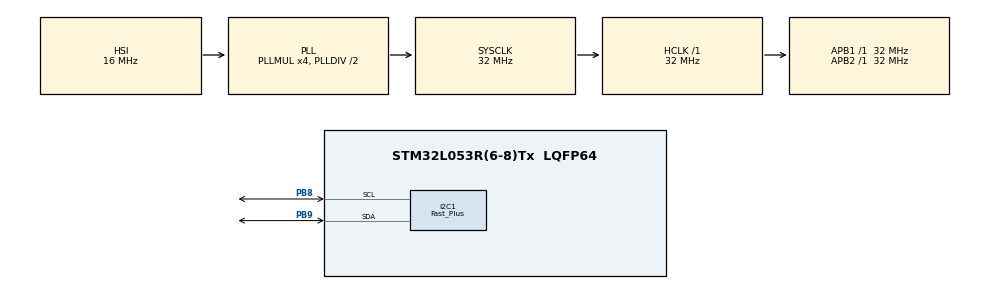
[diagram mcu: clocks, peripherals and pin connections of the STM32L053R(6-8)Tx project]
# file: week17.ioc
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I2C1.I2C_Speed_Mode=I2C_Fast_Plus
I2C1.Timing=0x00100413
Mcu.Family=STM32L0
Mcu.Name=STM32L053R(6-8)Tx
Mcu.Package=LQFP64
PA13.Mode=Serial_Wire
PA13.Signal=SYS_SWDIO
PA14.Mode=Serial_Wire
PA14.Signal=SYS_SWCLK
PB8.Mode=I2C
PB8.Signal=I2C1_SCL
PB9.Mode=I2C
PB9.Signal=I2C1_SDA
PH0-OSC_IN.Mode=HSE-External-Oscillator
PH0-OSC_IN.Signal=RCC_OSC_IN
PH1-OSC_OUT.Mode=HSE-External-Oscillator
PH1-OSC_OUT.Signal=RCC_OSC_OUT
ProjectManager.HeapSize=0x200
ProjectManager.StackSize=0x400
ProjectManager.TargetToolchain=MDK-ARM V5.27
RCC.AHBFreq_Value=32000000
RCC.APB1Freq_Value=32000000
RCC.APB1TimFreq_Value=32000000
RCC.APB2Freq_Value=32000000
RCC.APB2TimFreq_Value=32000000
RCC.HCLKFreq_Value=32000000
RCC.HSE_VALUE=8000000
RCC.HSI16_VALUE=16000000
RCC.HSI48_VALUE=48000000
RCC.HSI_VALUE=16000000
RCC.LSE_VALUE=32768
RCC.MSI_VALUE=2097000
RCC.PLLMUL=RCC_PLLMUL_4
RCC.SYSCLKFreq_VALUE=32000000
RCC.SYSCLKSource=RCC_SYSCLKSOURCE_PLLCLK
RCC.VCOOutputFreq_Value=64000000
board=custom

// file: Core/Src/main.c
/* USER CODE BEGIN Header */
/**
  ******************************************************************************
  * @file           : main.c
  * @brief          : Main program body
  ******************************************************************************
  * @attention
  *
  * <h2><center>&copy; Copyright (c) 2021 STMicroelectronics.
  * All rights reserved.</center></h2>
  *
  * This software component is licensed by ST under BSD 3-Clause license,
  * the "License"; You may not use this file except in compliance with the
  * License. You may obtain a copy of the License at:
  *                        opensource.org/licenses/BSD-3-Clause
  *
  ******************************************************************************
  */
/* USER CODE END Header */
#include "main.h"
#include "i2c.h"
#include "gpio.h"

void SystemClock_Config(void);

/* USER CODE BEGIN 0 */
extern void oled_init(void);
extern void oled_update(void);
extern void oled_draw_pixel(uint8_t, uint8_t, uint8_t);
extern void oled_draw_bitmap(uint8_t, uint8_t, uint8_t*, uint8_t, uint8_t);
extern HAL_StatusTypeDef ssd1306_send_cmd(uint8_t);

uint8_t image_rabbit[366] = { 0X22,0X01,0X2D,0X00,0X40,0X00,
0X00,0X00,0X00,0X00,0X00,0X00,0X00,0X00,0X00,0X00,0X00,0X00,0X00,0X80,0X40,0X20,
0X20,0XC0,0X80,0X00,0X00,0X00,0X00,0X00,0X00,0XC0,0X60,0X20,0X20,0XC0,0X00,0X00,
0X00,0X00,0X00,0X00,0X00,0X00,0X00,0X00,0X00,0X00,0X00,0X00,0X00,0X00,0X00,0X00,
0X00,0X00,0X00,0X00,0X00,0X00,0X00,0X00,0X00,0X00,0X07,0X7C,0X80,0X00,0X00,0X3F,
0XC0,0X00,0X00,0X00,0X00,0X00,0XFF,0X00,0X00,0X00,0XFF,0X00,0X00,0X00,0X00,0X00,
0X00,0X00,0X00,0X00,0X00,0X00,0X00,0X00,0X00,0X00,0X00,0X00,0X00,0X00,0X00,0X00,
0X00,0XC0,0X60,0X30,0X18,0X08,0X04,0X04,0X02,0X03,0X00,0X00,0X00,0X01,0X01,0X01,
0X01,0X01,0X01,0X01,0X00,0X00,0X00,0X01,0X01,0X02,0X02,0X04,0X08,0X10,0X20,0X40,
0X80,0X00,0X00,0X00,0X00,0X00,0X00,0X00,0X00,0X00,0X00,0XE0,0X1C,0X03,0X00,0X00,
0X00,0X10,0X10,0X10,0X18,0X18,0X08,0X08,0X08,0X08,0X08,0X00,0X00,0X00,0X00,0X00,
0X08,0X08,0X08,0X08,0X08,0X08,0X08,0X08,0X08,0X08,0X00,0X00,0X00,0X01,0X0E,0XF0,
0X00,0X00,0X00,0X00,0X00,0X00,0X00,0X00,0X03,0X1C,0X60,0X80,0X00,0X00,0X00,0X00,
0X00,0X00,0X00,0X00,0X00,0X00,0X00,0X00,0X00,0X00,0X00,0X00,0X00,0X00,0X00,0X00,
0X00,0X00,0X00,0X00,0X00,0X00,0X00,0X00,0X00,0X80,0XC0,0X38,0X07,0X00,0X00,0X00,
0X00,0X00,0X00,0X00,0X00,0X00,0X00,0X00,0X00,0X01,0X02,0X04,0X0C,0X88,0X78,0X10,
0X90,0X10,0X20,0X20,0X00,0X00,0X00,0X00,0X00,0X00,0X00,0X00,0X00,0X10,0X90,0X10,
0X78,0X88,0X08,0X04,0X06,0X03,0X01,0X00,0X00,0X00,0X00,0X00,0X00,0X00,0X00,0X80,
0X80,0X80,0X80,0X80,0X80,0X00,0X00,0X00,0X00,0XFC,0X07,0XF0,0X1F,0X80,0X80,0X80,
0X80,0X00,0X00,0X00,0X00,0X00,0X00,0X00,0X00,0X00,0X80,0X80,0X0E,0XF0,0X07,0X7C,
0X80,0X00,0X80,0X80,0X00,0XC0,0X00,0X00,0X80,0X00,0X00,0X00,0X00,0X00,0X00,0X00,
0X00,0X00,0X00,0X01,0X01,0X01,0X01,0X01,0X01,0X01,0X01,0X00,0X00,0X00,0X01,0X01,
0X01,0X01,0X01,0X01,0X01,0X01,0X01,0X01,0X01,0X01,0X01,0X01,0X01,0X01,0X01,0X00,
0X00,0X00,0X00,0X00,0X00,0X00,0X00,0X00,};

uint8_t image_hi[526] = { 0X22,0X01,0X41,0X00,0X40,0X00,
0X00,0X00,0X00,0X00,0X00,0X00,0X00,0X00,0X00,0X00,0X00,0X00,0X00,0X00,0X00,0X00,
0X00,0X00,0X00,0X00,0X00,0X00,0X00,0X00,0X00,0X00,0X00,0X00,0X00,0X00,0X00,0X00,
0X00,0X00,0X00,0X00,0X00,0X00,0X00,0X00,0X00,0X00,0X00,0X00,0X00,0X00,0X00,0X00,
0X00,0X00,0X00,0X00,0X00,0X00,0X00,0X00,0X00,0X00,0X00,0X00,0X00,0X00,0X00,0X00,
0X00,0X00,0X00,0X00,0X00,0X00,0X00,0X00,0X00,0X00,0X00,0X00,0X00,0X00,0X00,0X00,
0X00,0X00,0X00,0X00,0X00,0X00,0X00,0X00,0X00,0X40,0XC0,0X80,0X80,0X80,0X00,0X00,
0X00,0X00,0X00,0X00,0X00,0XE0,0XFE,0XFE,0X3C,0X08,0X00,0X00,0X00,0X00,0X00,0X00,
0X00,0X00,0X80,0X80,0X80,0X80,0X80,0X00,0X00,0X00,0X00,0X00,0X00,0X00,0X00,0X00,
0X00,0X00,0X00,0X00,0X00,0X00,0X00,0X00,0X00,0X00,0X00,0X00,0X00,0X00,0X00,0X00,
0X00,0X00,0X00,0X00,0X00,0X00,0X00,0X00,0X00,0X00,0X00,0X00,0X03,0X07,0X07,0X07,
0X00,0X00,0X80,0XE0,0X78,0X1E,0X0F,0X0F,0X0C,0X0C,0X04,0X04,0X06,0X06,0X06,0X02,
0X02,0X03,0X03,0X03,0X03,0X03,0X03,0X01,0X01,0X00,0X00,0X00,0X00,0X00,0X00,0X00,
0X00,0X00,0X00,0X00,0X00,0X00,0X00,0X00,0X04,0X1C,0XFC,0XF8,0X08,0X04,0X04,0X04,
0X04,0X06,0XE7,0XFF,0XFE,0X3E,0X0C,0X00,0X01,0X03,0X0F,0X1E,0X3E,0X1C,0X00,0X00,
0X00,0X00,0X00,0X01,0X00,0X1C,0XFC,0XFC,0X0C,0X04,0X04,0X04,0XC4,0X86,0X82,0X82,
0X02,0X02,0X03,0X03,0X03,0XFF,0XFF,0XFE,0X1E,0X00,0X00,0X00,0X00,0X00,0X00,0X00,
0X00,0X00,0X00,0X00,0X00,0X00,0X00,0X00,0X00,0X00,0X00,0X03,0XFF,0XF0,0XC0,0X40,
0X40,0X60,0X60,0X7F,0X7F,0X03,0X00,0X00,0X00,0X00,0X00,0X00,0X00,0XC0,0X60,0X08,
0X00,0X40,0X40,0XC0,0XE0,0XE0,0XF8,0XFF,0X7F,0X60,0X20,0X20,0X20,0X20,0X21,0X23,
0X23,0X23,0X20,0X20,0X20,0X30,0XFF,0XFF,0XFF,0X30,0X30,0X30,0X38,0X38,0X38,0X30,
0X30,0X20,0X00,0X00,0X00,0X00,0X00,0X00,0X00,0X00,0X00,0X00,0X00,0X00,0X01,0X00,
0X00,0X00,0X00,0X00,0X00,0X00,0X00,0X80,0XC0,0XC0,0XF0,0XF8,0X7C,0X0F,0X03,0X00,
0X00,0X00,0X00,0X00,0X80,0XF0,0XFC,0X3F,0X01,0X00,0X00,0X00,0X00,0X00,0X02,0X06,
0X1E,0X9C,0X9C,0X80,0X00,0X80,0XE0,0XFF,0XFF,0X80,0X80,0X00,0X00,0X00,0X00,0X00,
0X00,0X00,0X00,0X00,0X00,0X00,0X00,0X00,0X00,0X00,0X00,0X00,0X00,0X00,0X00,0X00,
0X00,0X00,0X00,0X00,0X00,0X00,0X00,0X00,0X03,0X1F,0X3F,0X1F,0X01,0X00,0X00,0X00,
0X00,0X00,0X00,0X00,0X0F,0X0F,0X07,0X03,0X03,0X03,0X01,0X01,0X01,0X01,0X01,0X81,
0X81,0X01,0X01,0X01,0X01,0XC1,0XF1,0XFF,0X7F,0X07,0X01,0X01,0X03,0X03,0X03,0X07,
0X06,0X00,0X00,0X00,0X00,0X00,0X00,0X00,0X00,0X00,0X00,0X00,0X00,0X00,0X00,0X00,
0X00,0X00,0X00,0X00,0X00,0X00,0X00,0X00,0X00,0X00,0X00,0X00,0X00,0X00,0X00,0X00,
0X00,0X00,0X00,0X00,0X00,0X00,0X00,0X00,0X00,0X00,0X00,0X00,0X00,0X00,0X00,0X00,
0X00,0X00,0X03,0X07,0X0F,0X1F,0X0F,0X07,0X03,0X00,0X00,0X00,0X00,0X00,0X00,0X00,
0X00,0X00,0X00,0X00,0X00,0X00,0X00,0X00,};

/* USER CODE END 0 */

int main(void)
{

  /* MCU Configuration--------------------------------------------------------*/

  /* Reset of all peripherals, Initializes the Flash interface and the Systick. */
  HAL_Init();

  /* Configure the system clock */
  SystemClock_Config();

  /* Initialize all configured peripherals */
  MX_GPIO_Init();
  MX_I2C1_Init();
  /* USER CODE BEGIN 2 */
  oled_init();
  oled_draw_bitmap(0, 0, image_rabbit, 45, 8);
  oled_draw_bitmap(46, 0, image_hi, 65, 8);
  oled_update();
  /* USER CODE END 2 */

  /* Infinite loop */
  while (1)
  {

  }
}

void SystemClock_Config(void)
{
  RCC_OscInitTypeDef RCC_OscInitStruct = {0};
  RCC_ClkInitTypeDef RCC_ClkInitStruct = {0};
  RCC_PeriphCLKInitTypeDef PeriphClkInit = {0};

  /** Configure the main internal regulator output voltage
  */
  __HAL_PWR_VOLTAGESCALING_CONFIG(PWR_REGULATOR_VOLTAGE_SCALE1);
  /** Initializes the RCC Oscillators according to the specified parameters
  * in the RCC_OscInitTypeDef structure.
  */
  RCC_OscInitStruct.OscillatorType = RCC_OSCILLATORTYPE_HSI;
  RCC_OscInitStruct.HSIState = RCC_HSI_ON;
  RCC_OscInitStruct.HSICalibrationValue = RCC_HSICALIBRATION_DEFAULT;
  RCC_OscInitStruct.PLL.PLLState = RCC_PLL_ON;
  RCC_OscInitStruct.PLL.PLLSource = RCC_PLLSOURCE_HSI;
  RCC_OscInitStruct.PLL.PLLMUL = RCC_PLLMUL_4;
  RCC_OscInitStruct.PLL.PLLDIV = RCC_PLLDIV_2;
  if (HAL_RCC_OscConfig(&RCC_OscInitStruct) != HAL_OK)
  {
    Error_Handler();
  }
  /** Initializes the CPU, AHB and APB buses clocks
  */
  RCC_ClkInitStruct.ClockType = RCC_CLOCKTYPE_HCLK|RCC_CLOCKTYPE_SYSCLK
                              |RCC_CLOCKTYPE_PCLK1|RCC_CLOCKTYPE_PCLK2;
  RCC_ClkInitStruct.SYSCLKSource = RCC_SYSCLKSOURCE_PLLCLK;
  RCC_ClkInitStruct.AHBCLKDivider = RCC_SYSCLK_DIV1;
  RCC_ClkInitStruct.APB1CLKDivider = RCC_HCLK_DIV1;
  RCC_ClkInitStruct.APB2CLKDivider = RCC_HCLK_DIV1;

  if (HAL_RCC_ClockConfig(&RCC_ClkInitStruct, FLASH_LATENCY_1) != HAL_OK)
  {
    Error_Handler();
  }
  PeriphClkInit.PeriphClockSelection = RCC_PERIPHCLK_I2C1;
  PeriphClkInit.I2c1ClockSelection = RCC_I2C1CLKSOURCE_PCLK1;
  if (HAL_RCCEx_PeriphCLKConfig(&PeriphClkInit) != HAL_OK)
  {
    Error_Handler();
  }
}

void Error_Handler(void)
{
  __disable_irq();
  while (1)
  {
  }
}

/************************ (C) COPYRIGHT STMicroelectronics *****END OF FILE****/
